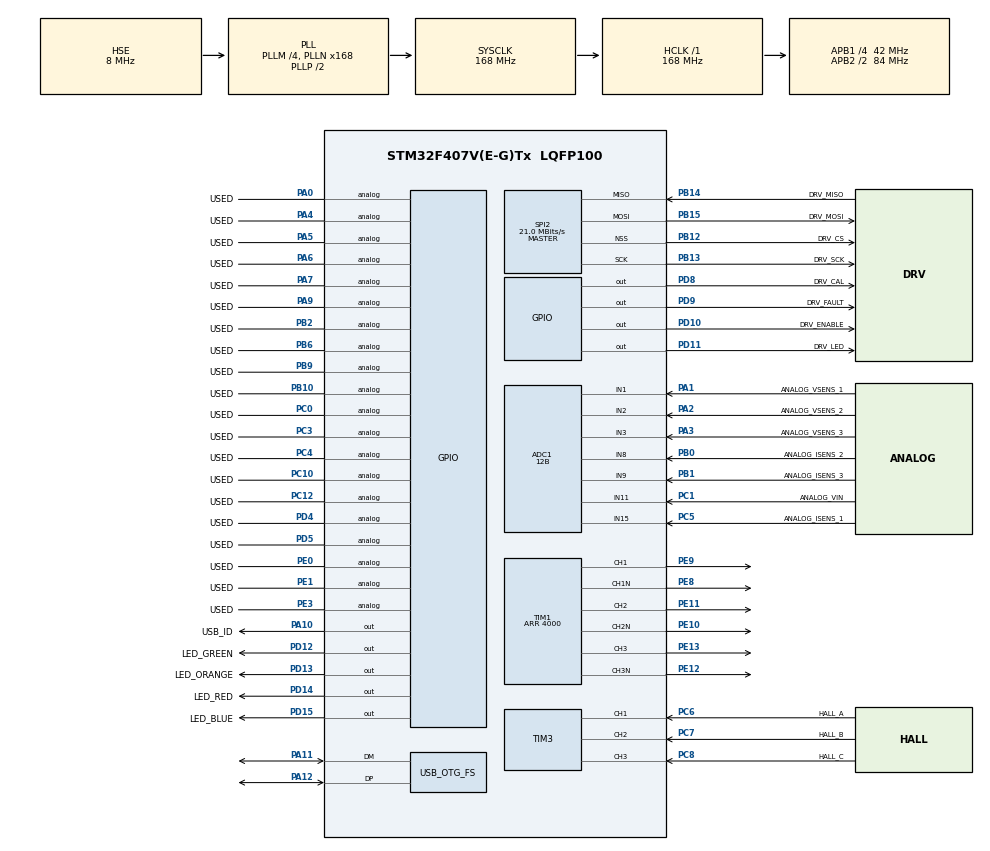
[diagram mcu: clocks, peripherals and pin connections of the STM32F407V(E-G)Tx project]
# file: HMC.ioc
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ADC1.Channel-155\#ChannelRegularConversion=ADC_CHANNEL_1
ADC1.ClockPrescaler=ADC_CLOCK_SYNC_PCLK_DIV4
ADC1.ContinuousConvMode=DISABLE
ADC1.DMAContinuousRequests=DISABLE
ADC1.DataAlign=ADC_DATAALIGN_RIGHT
ADC1.DiscontinuousConvMode=DISABLE
ADC1.EOCSelection=ADC_EOC_SINGLE_CONV
ADC1.EnableAnalogWatchDog=false
ADC1.ExternalTrigConv=ADC_SOFTWARE_START
ADC1.ExternalTrigConvEdge=ADC_EXTERNALTRIGCONVEDGE_NONE
ADC1.InjNumberOfConversion=0
ADC1.NbrOfConversion=1
ADC1.NbrOfConversionFlag=1
ADC1.Rank-155\#ChannelRegularConversion=1
ADC1.Resolution=ADC_RESOLUTION_12B
ADC1.SamplingTime-155\#ChannelRegularConversion=ADC_SAMPLETIME_3CYCLES
ADC1.ScanConvMode=DISABLE
ADC1.master=1
Mcu.Family=STM32F4
Mcu.Name=STM32F407V(E-G)Tx
Mcu.Package=LQFP100
NVIC.OTG_FS_IRQn=true\:0\:0\:false\:false\:true\:false
NVIC.PriorityGroup=NVIC_PRIORITYGROUP_4
NVIC.TIM1_TRG_COM_TIM11_IRQn=true\:0\:0\:false\:false\:true\:true
NVIC.TIM3_IRQn=true\:0\:0\:false\:false\:true\:true
PA0-WKUP.GPIO_Label=USED
PA0-WKUP.Signal=GPIO_Analog
PA1.GPIO_Label=ANALOG_VSENS_1
PA1.Signal=ADCx_IN1
PA10.GPIO_Label=USB_ID
PA10.Signal=GPIO_Output
PA11.Mode=Device_Only
PA11.Signal=USB_OTG_FS_DM
PA12.Mode=Device_Only
PA12.Signal=USB_OTG_FS_DP
PA13.Mode=Trace_Asynchronous_SW
PA13.Signal=SYS_JTMS-SWDIO
PA14.Mode=Trace_Asynchronous_SW
PA14.Signal=SYS_JTCK-SWCLK
PA2.GPIO_Label=ANALOG_VSENS_2
PA2.Signal=ADCx_IN2
PA3.GPIO_Label=ANALOG_VSENS_3
PA3.Signal=ADCx_IN3
PA4.GPIO_Label=USED
PA4.Signal=GPIO_Analog
PA5.GPIO_Label=USED
PA5.Signal=GPIO_Analog
PA6.GPIO_Label=USED
PA6.Signal=GPIO_Analog
PA7.GPIO_Label=USED
PA7.Signal=GPIO_Analog
PA9.GPIO_Label=USED
PA9.Signal=GPIO_Analog
PB0.GPIO_Label=ANALOG_ISENS_2
PB0.Signal=ADCx_IN8
PB1.GPIO_Label=ANALOG_ISENS_3
PB1.Signal=ADCx_IN9
PB10.GPIO_Label=USED
PB10.Signal=GPIO_Analog
PB12.GPIO_Label=DRV_CS
PB12.Mode=NSS_Signal_Hard_Output
PB12.Signal=SPI2_NSS
PB13.GPIO_Label=DRV_SCK
PB13.Mode=Full_Duplex_Master
PB13.Signal=SPI2_SCK
PB14.GPIO_Label=DRV_MISO
PB14.Mode=Full_Duplex_Master
PB14.Signal=SPI2_MISO
PB15.GPIO_Label=DRV_MOSI
PB15.Mode=Full_Duplex_Master
PB15.Signal=SPI2_MOSI
PB2.GPIO_Label=USED
PB2.Signal=GPIO_Analog
PB3.Mode=Trace_Asynchronous_SW
PB3.Signal=SYS_JTDO-SWO
PB6.GPIO_Label=USED
PB6.Signal=GPIO_Analog
PB9.GPIO_Label=USED
PB9.Signal=GPIO_Analog
PC0.GPIO_Label=USED
PC0.Signal=GPIO_Analog
PC1.GPIO_Label=ANALOG_VIN
PC1.Signal=ADCx_IN11
PC10.GPIO_Label=USED
PC10.Signal=GPIO_Analog
PC12.GPIO_Label=USED
PC12.Signal=GPIO_Analog
PC14-OSC32_IN.Mode=LSE-External-Oscillator
PC14-OSC32_IN.Signal=RCC_OSC32_IN
PC15-OSC32_OUT.Mode=LSE-External-Oscillator
PC15-OSC32_OUT.Signal=RCC_OSC32_OUT
PC3.GPIO_Label=USED
PC3.Signal=GPIO_Analog
PC4.GPIO_Label=USED
PC4.Signal=GPIO_Analog
PC5.GPIO_Label=ANALOG_ISENS_1
PC5.Signal=ADCx_IN15
PC6.GPIO_Label=HALL_A
PC6.Signal=S_TIM3_CH1
PC7.GPIO_Label=HALL_B
PC7.Signal=S_TIM3_CH2
PC8.GPIO_Label=HALL_C
PC8.Signal=S_TIM3_CH3
PD10.GPIO_Label=DRV_ENABLE
PD10.Signal=GPIO_Output
PD11.GPIO_Label=DRV_LED
PD11.Signal=GPIO_Output
PD12.GPIO_Label=LED_GREEN
PD12.Signal=GPIO_Output
PD13.GPIO_Label=LED_ORANGE
PD13.Signal=GPIO_Output
PD14.GPIO_Label=LED_RED
PD14.Signal=GPIO_Output
PD15.GPIO_Label=LED_BLUE
PD15.Signal=GPIO_Output
PD4.GPIO_Label=USED
PD4.Signal=GPIO_Analog
PD5.GPIO_Label=USED
PD5.Signal=GPIO_Analog
PD8.GPIO_Label=DRV_CAL
PD8.Signal=GPIO_Output
PD9.GPIO_Label=DRV_FAULT
PD9.Signal=GPIO_Output
PE0.GPIO_Label=USED
PE0.Signal=GPIO_Analog
PE1.GPIO_Label=USED
PE1.Signal=GPIO_Analog
PE10.GPIO_Speed=GPIO_SPEED_FREQ_VERY_HIGH
PE10.Mode=Output Compare2 CH2 CH2N
PE10.Signal=TIM1_CH2N
PE11.GPIO_Speed=GPIO_SPEED_FREQ_VERY_HIGH
PE11.Signal=S_TIM1_CH2
PE12.GPIO_Speed=GPIO_SPEED_FREQ_VERY_HIGH
PE12.Mode=Output Compare3 CH3 CH3N
PE12.Signal=TIM1_CH3N
PE13.GPIO_Speed=GPIO_SPEED_FREQ_VERY_HIGH
PE13.Signal=S_TIM1_CH3
PE3.GPIO_Label=USED
PE3.Signal=GPIO_Analog
PE8.GPIO_PuPd=GPIO_NOPULL
PE8.GPIO_Speed=GPIO_SPEED_FREQ_VERY_HIGH
PE8.Mode=Output Compare1 CH1 CH1N
PE8.Signal=TIM1_CH1N
PE9.GPIO_Speed=GPIO_SPEED_FREQ_VERY_HIGH
PE9.Signal=S_TIM1_CH1
PH0-OSC_IN.Mode=HSE-External-Oscillator
PH0-OSC_IN.Signal=RCC_OSC_IN
PH1-OSC_OUT.Mode=HSE-External-Oscillator
PH1-OSC_OUT.Signal=RCC_OSC_OUT
ProjectManager.HeapSize=0x200
ProjectManager.StackSize=0x400
ProjectManager.TargetToolchain=Makefile
RCC.48MHZClocksFreq_Value=48000000
RCC.AHBFreq_Value=168000000
RCC.APB1CLKDivider=RCC_HCLK_DIV4
RCC.APB1Freq_Value=42000000
RCC.APB1TimFreq_Value=84000000
RCC.APB2CLKDivider=RCC_HCLK_DIV2
RCC.APB2Freq_Value=84000000
RCC.APB2TimFreq_Value=168000000
RCC.CortexFreq_Value=168000000
RCC.HCLKFreq_Value=168000000
RCC.HSE_VALUE=8000000
RCC.HSI_VALUE=16000000
RCC.PLLM=4
RCC.PLLN=168
RCC.PLLQ=7
RCC.SYSCLKFreq_VALUE=168000000
RCC.SYSCLKSource=RCC_SYSCLKSOURCE_PLLCLK
RCC.VCOOutputFreq_Value=336000000
SH.ADCx_IN1.0=ADC1_IN1,IN1
SH.ADCx_IN11.0=ADC1_IN11,IN11
SH.ADCx_IN15.0=ADC1_IN15,IN15
SH.ADCx_IN2.0=ADC1_IN2,IN2
SH.ADCx_IN3.0=ADC1_IN3,IN3
SH.ADCx_IN8.0=ADC1_IN8,IN8
SH.ADCx_IN9.0=ADC1_IN9,IN9
SH.S_TIM1_CH1.0=TIM1_CH1,Output Compare1 CH1 CH1N
SH.S_TIM1_CH2.0=TIM1_CH2,Output Compare2 CH2 CH2N
SH.S_TIM1_CH3.0=TIM1_CH3,Output Compare3 CH3 CH3N
SH.S_TIM3_CH1.0=TIM3_CH1,Xored_Inputs_Hall_Sensor_Interface
SH.S_TIM3_CH2.0=TIM3_CH2,Xored_Inputs_Hall_Sensor_Interface
SH.S_TIM3_CH3.0=TIM3_CH3,Xored_Inputs_Hall_Sensor_Interface
SPI2.CalculateBaudRate=21.0 MBits/s
SPI2.Direction=SPI_DIRECTION_2LINES
SPI2.Mode=SPI_MODE_MASTER
SPI2.VirtualNSS=VM_NSSHARD
SPI2.VirtualType=VM_MASTER
TIM1.AutomaticOutput=TIM_AUTOMATICOUTPUT_ENABLE
TIM1.Channel-Output\ Compare1\ CH1\ CH1N=TIM_CHANNEL_1
TIM1.Channel-Output\ Compare2\ CH2\ CH2N=TIM_CHANNEL_2
TIM1.Channel-Output\ Compare3\ CH3\ CH3N=TIM_CHANNEL_3
TIM1.DeadTime=7
TIM1.OffStateIDLEMode=TIM_OSSI_ENABLE
TIM1.OffStateRunMode=TIM_OSSR_ENABLE
TIM1.Period=4000
TIM1.TIM_MasterSlaveMode=TIM_MASTERSLAVEMODE_DISABLE
USB_DEVICE.CLASS_NAME_FS=CDC
USB_DEVICE.VirtualMode-CDC_FS=Cdc
USB_DEVICE.VirtualModeFS=Cdc_FS
USB_OTG_FS.VirtualMode=Device_Only
VP_TIM1_VS_ClockSourceITR.Mode=TriggerSource_ITR2
VP_USB_DEVICE_VS_USB_DEVICE_CDC_FS.Mode=CDC_FS
board=HMC

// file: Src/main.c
/**
  ******************************************************************************
  * @file           : main.c
  * @brief          : Main program body
  ******************************************************************************
  * This notice applies to any and all portions of this file
  * that are not between comment pairs USER CODE BEGIN and
  * USER CODE END. Other portions of this file, whether
  * inserted by the user or by software development tools
  * are owned by their respective copyright owners.
  *
  * Copyright (c) 2018 STMicroelectronics International N.V.
  * All rights reserved.
  *
  * Redistribution and use in source and binary forms, with or without
  * modification, are permitted, provided that the following conditions are met:
  *
  * 1. Redistribution of source code must retain the above copyright notice,
  *    this list of conditions and the following disclaimer.
  * 2. Redistributions in binary form must reproduce the above copyright notice,
  *    this list of conditions and the following disclaimer in the documentation
  *    and/or other materials provided with the distribution.
  * 3. Neither the name of STMicroelectronics nor the names of other
  *    contributors to this software may be used to endorse or promote products
  *    derived from this software without specific written permission.
  * 4. This software, including modifications and/or derivative works of this
  *    software, must execute solely and exclusively on microcontroller or
  *    microprocessor devices manufactured by or for STMicroelectronics.
  * 5. Redistribution and use of this software other than as permitted under
  *    this license is void and will automatically terminate your rights under
  *    this license.
  *
  * THIS SOFTWARE IS PROVIDED BY STMICROELECTRONICS AND CONTRIBUTORS "AS IS"
  * AND ANY EXPRESS, IMPLIED OR STATUTORY WARRANTIES, INCLUDING, BUT NOT
  * LIMITED TO, THE IMPLIED WARRANTIES OF MERCHANTABILITY, FITNESS FOR A
  * PARTICULAR PURPOSE AND NON-INFRINGEMENT OF THIRD PARTY INTELLECTUAL PROPERTY
  * RIGHTS ARE DISCLAIMED TO THE FULLEST EXTENT PERMITTED BY LAW. IN NO EVENT
  * SHALL STMICROELECTRONICS OR CONTRIBUTORS BE LIABLE FOR ANY DIRECT, INDIRECT,
  * INCIDENTAL, SPECIAL, EXEMPLARY, OR CONSEQUENTIAL DAMAGES (INCLUDING, BUT NOT
  * LIMITED TO, PROCUREMENT OF SUBSTITUTE GOODS OR SERVICES; LOSS OF USE, DATA,
  * OR PROFITS; OR BUSINESS INTERRUPTION) HOWEVER CAUSED AND ON ANY THEORY OF
  * LIABILITY, WHETHER IN CONTRACT, STRICT LIABILITY, OR TORT (INCLUDING
  * NEGLIGENCE OR OTHERWISE) ARISING IN ANY WAY OUT OF THE USE OF THIS SOFTWARE,
  * EVEN IF ADVISED OF THE POSSIBILITY OF SUCH DAMAGE.
  *
  ******************************************************************************
  */
#include "main.h"
#include "stm32f4xx_hal.h"
#include "usb_device.h"

/* USER CODE BEGIN Includes */
#include "time.h"
#include "motor.h"
#include "usbd_cdc_if.h"
/* USER CODE END Includes */

ADC_HandleTypeDef hadc1;

SPI_HandleTypeDef hspi2;

TIM_HandleTypeDef htim1;
TIM_HandleTypeDef htim3;

/* USER CODE BEGIN PV */
/* Private variables ---------------------------------------------------------*/

/* USER CODE END PV */

void SystemClock_Config(void);
static void MX_GPIO_Init(void);
static void MX_TIM1_Init(void);
static void MX_ADC1_Init(void);
static void MX_SPI2_Init(void);
static void MX_TIM3_Init(void);

void HAL_TIM_MspPostInit(TIM_HandleTypeDef *htim);

/* USER CODE BEGIN PFP */
/* Private function prototypes -----------------------------------------------*/

/* USER CODE END PFP */

int main(void)
{

  /* MCU Configuration----------------------------------------------------------*/

  /* Reset of all peripherals, Initializes the Flash interface and the Systick. */
  HAL_Init();

  /* Configure the system clock */
  SystemClock_Config();

  /* Initialize all configured peripherals */
  MX_GPIO_Init();
  MX_TIM1_Init();
  MX_ADC1_Init();
  MX_SPI2_Init();
  MX_USB_DEVICE_Init();
  MX_TIM3_Init();

  /* Infinite loop */
	while (1)
	{

  /* USER CODE BEGIN 3 */
		static time timer = 0;

		if(time_elapsed_now(timer) > 100)
		{
			timer = time_get();

      CDC_Transmit_FS((uint8_t *)"hello\r\n", 5);

			HAL_GPIO_TogglePin(LED_BLUE_GPIO_Port, LED_BLUE_Pin);
			HAL_GPIO_TogglePin(LED_RED_GPIO_Port, LED_RED_Pin);
			HAL_GPIO_TogglePin(LED_ORANGE_GPIO_Port, LED_ORANGE_Pin);
			HAL_GPIO_TogglePin(LED_GREEN_GPIO_Port, LED_GREEN_Pin);
		}
	}
  /* USER CODE END 3 */

}

void SystemClock_Config(void)
{

  RCC_OscInitTypeDef RCC_OscInitStruct;
  RCC_ClkInitTypeDef RCC_ClkInitStruct;

    /**Configure the main internal regulator output voltage
    */
  __HAL_RCC_PWR_CLK_ENABLE();

  __HAL_PWR_VOLTAGESCALING_CONFIG(PWR_REGULATOR_VOLTAGE_SCALE1);

    /**Initializes the CPU, AHB and APB busses clocks
    */
  RCC_OscInitStruct.OscillatorType = RCC_OSCILLATORTYPE_HSE;
  RCC_OscInitStruct.HSEState = RCC_HSE_ON;
  RCC_OscInitStruct.PLL.PLLState = RCC_PLL_ON;
  RCC_OscInitStruct.PLL.PLLSource = RCC_PLLSOURCE_HSE;
  RCC_OscInitStruct.PLL.PLLM = 4;
  RCC_OscInitStruct.PLL.PLLN = 168;
  RCC_OscInitStruct.PLL.PLLP = RCC_PLLP_DIV2;
  RCC_OscInitStruct.PLL.PLLQ = 7;
  if (HAL_RCC_OscConfig(&RCC_OscInitStruct) != HAL_OK)
  {
    _Error_Handler(__FILE__, __LINE__);
  }

    /**Initializes the CPU, AHB and APB busses clocks
    */
  RCC_ClkInitStruct.ClockType = RCC_CLOCKTYPE_HCLK|RCC_CLOCKTYPE_SYSCLK
                              |RCC_CLOCKTYPE_PCLK1|RCC_CLOCKTYPE_PCLK2;
  RCC_ClkInitStruct.SYSCLKSource = RCC_SYSCLKSOURCE_PLLCLK;
  RCC_ClkInitStruct.AHBCLKDivider = RCC_SYSCLK_DIV1;
  RCC_ClkInitStruct.APB1CLKDivider = RCC_HCLK_DIV4;
  RCC_ClkInitStruct.APB2CLKDivider = RCC_HCLK_DIV2;

  if (HAL_RCC_ClockConfig(&RCC_ClkInitStruct, FLASH_LATENCY_5) != HAL_OK)
  {
    _Error_Handler(__FILE__, __LINE__);
  }

    /**Configure the Systick interrupt time
    */
  HAL_SYSTICK_Config(HAL_RCC_GetHCLKFreq()/1000);

    /**Configure the Systick
    */
  HAL_SYSTICK_CLKSourceConfig(SYSTICK_CLKSOURCE_HCLK);

  /* SysTick_IRQn interrupt configuration */
  HAL_NVIC_SetPriority(SysTick_IRQn, 0, 0);
}

/* ADC1 init function */
static void MX_ADC1_Init(void)
{

  ADC_ChannelConfTypeDef sConfig;

    /**Configure the global features of the ADC (Clock, Resolution, Data Alignment and number of conversion)
    */
  hadc1.Instance = ADC1;
  hadc1.Init.ClockPrescaler = ADC_CLOCK_SYNC_PCLK_DIV4;
  hadc1.Init.Resolution = ADC_RESOLUTION_12B;
  hadc1.Init.ScanConvMode = DISABLE;
  hadc1.Init.ContinuousConvMode = DISABLE;
  hadc1.Init.DiscontinuousConvMode = DISABLE;
  hadc1.Init.ExternalTrigConvEdge = ADC_EXTERNALTRIGCONVEDGE_NONE;
  hadc1.Init.ExternalTrigConv = ADC_SOFTWARE_START;
  hadc1.Init.DataAlign = ADC_DATAALIGN_RIGHT;
  hadc1.Init.NbrOfConversion = 1;
  hadc1.Init.DMAContinuousRequests = DISABLE;
  hadc1.Init.EOCSelection = ADC_EOC_SINGLE_CONV;
  if (HAL_ADC_Init(&hadc1) != HAL_OK)
  {
    _Error_Handler(__FILE__, __LINE__);
  }

    /**Configure for the selected ADC regular channel its corresponding rank in the sequencer and its sample time.
    */
  sConfig.Channel = ADC_CHANNEL_1;
  sConfig.Rank = 1;
  sConfig.SamplingTime = ADC_SAMPLETIME_3CYCLES;
  if (HAL_ADC_ConfigChannel(&hadc1, &sConfig) != HAL_OK)
  {
    _Error_Handler(__FILE__, __LINE__);
  }

}

/* SPI2 init function */
static void MX_SPI2_Init(void)
{

  /* SPI2 parameter configuration*/
  hspi2.Instance = SPI2;
  hspi2.Init.Mode = SPI_MODE_MASTER;
  hspi2.Init.Direction = SPI_DIRECTION_2LINES;
  hspi2.Init.DataSize = SPI_DATASIZE_8BIT;
  hspi2.Init.CLKPolarity = SPI_POLARITY_LOW;
  hspi2.Init.CLKPhase = SPI_PHASE_1EDGE;
  hspi2.Init.NSS = SPI_NSS_HARD_OUTPUT;
  hspi2.Init.BaudRatePrescaler = SPI_BAUDRATEPRESCALER_2;
  hspi2.Init.FirstBit = SPI_FIRSTBIT_MSB;
  hspi2.Init.TIMode = SPI_TIMODE_DISABLE;
  hspi2.Init.CRCCalculation = SPI_CRCCALCULATION_DISABLE;
  hspi2.Init.CRCPolynomial = 10;
  if (HAL_SPI_Init(&hspi2) != HAL_OK)
  {
    _Error_Handler(__FILE__, __LINE__);
  }

}

/* TIM1 init function */
static void MX_TIM1_Init(void)
{

  TIM_SlaveConfigTypeDef sSlaveConfig;
  TIM_MasterConfigTypeDef sMasterConfig;
  TIM_OC_InitTypeDef sConfigOC;
  TIM_BreakDeadTimeConfigTypeDef sBreakDeadTimeConfig;

  htim1.Instance = TIM1;
  htim1.Init.Prescaler = 0;
  htim1.Init.CounterMode = TIM_COUNTERMODE_UP;
  htim1.Init.Period = 4000;
  htim1.Init.ClockDivision = TIM_CLOCKDIVISION_DIV1;
  htim1.Init.RepetitionCounter = 0;
  if (HAL_TIM_Base_Init(&htim1) != HAL_OK)
  {
    _Error_Handler(__FILE__, __LINE__);
  }

  if (HAL_TIM_OC_Init(&htim1) != HAL_OK)
  {
    _Error_Handler(__FILE__, __LINE__);
  }

  sSlaveConfig.SlaveMode = TIM_SLAVEMODE_DISABLE;
  sSlaveConfig.InputTrigger = TIM_TS_ITR2;
  if (HAL_TIM_SlaveConfigSynchronization(&htim1, &sSlaveConfig) != HAL_OK)
  {
    _Error_Handler(__FILE__, __LINE__);
  }

  sMasterConfig.MasterOutputTrigger = TIM_TRGO_RESET;
  sMasterConfig.MasterSlaveMode = TIM_MASTERSLAVEMODE_DISABLE;
  if (HAL_TIMEx_MasterConfigSynchronization(&htim1, &sMasterConfig) != HAL_OK)
  {
    _Error_Handler(__FILE__, __LINE__);
  }

  sConfigOC.OCMode = TIM_OCMODE_TIMING;
  sConfigOC.Pulse = 0;
  sConfigOC.OCPolarity = TIM_OCPOLARITY_HIGH;
  sConfigOC.OCNPolarity = TIM_OCNPOLARITY_HIGH;
  sConfigOC.OCFastMode = TIM_OCFAST_DISABLE;
  sConfigOC.OCIdleState = TIM_OCIDLESTATE_RESET;
  sConfigOC.OCNIdleState = TIM_OCNIDLESTATE_RESET;
  if (HAL_TIM_OC_ConfigChannel(&htim1, &sConfigOC, TIM_CHANNEL_1) != HAL_OK)
  {
    _Error_Handler(__FILE__, __LINE__);
  }

  if (HAL_TIM_OC_ConfigChannel(&htim1, &sConfigOC, TIM_CHANNEL_2) != HAL_OK)
  {
    _Error_Handler(__FILE__, __LINE__);
  }

  if (HAL_TIM_OC_ConfigChannel(&htim1, &sConfigOC, TIM_CHANNEL_3) != HAL_OK)
  {
    _Error_Handler(__FILE__, __LINE__);
  }

  sBreakDeadTimeConfig.OffStateRunMode = TIM_OSSR_ENABLE;
  sBreakDeadTimeConfig.OffStateIDLEMode = TIM_OSSI_ENABLE;
  sBreakDeadTimeConfig.LockLevel = TIM_LOCKLEVEL_OFF;
  sBreakDeadTimeConfig.DeadTime = 7;
  sBreakDeadTimeConfig.BreakState = TIM_BREAK_DISABLE;
  sBreakDeadTimeConfig.BreakPolarity = TIM_BREAKPOLARITY_HIGH;
  sBreakDeadTimeConfig.AutomaticOutput = TIM_AUTOMATICOUTPUT_ENABLE;
  if (HAL_TIMEx_ConfigBreakDeadTime(&htim1, &sBreakDeadTimeConfig) != HAL_OK)
  {
    _Error_Handler(__FILE__, __LINE__);
  }

  HAL_TIM_MspPostInit(&htim1);

}

/* TIM3 init function */
static void MX_TIM3_Init(void)
{

  TIM_HallSensor_InitTypeDef sConfig;
  TIM_MasterConfigTypeDef sMasterConfig;

  htim3.Instance = TIM3;
  htim3.Init.Prescaler = 0;
  htim3.Init.CounterMode = TIM_COUNTERMODE_UP;
  htim3.Init.Period = 0;
  htim3.Init.ClockDivision = TIM_CLOCKDIVISION_DIV1;
  sConfig.IC1Polarity = TIM_ICPOLARITY_RISING;
  sConfig.IC1Prescaler = TIM_ICPSC_DIV1;
  sConfig.IC1Filter = 0;
  sConfig.Commutation_Delay = 0;
  if (HAL_TIMEx_HallSensor_Init(&htim3, &sConfig) != HAL_OK)
  {
    _Error_Handler(__FILE__, __LINE__);
  }

  sMasterConfig.MasterOutputTrigger = TIM_TRGO_OC2REF;
  sMasterConfig.MasterSlaveMode = TIM_MASTERSLAVEMODE_DISABLE;
  if (HAL_TIMEx_MasterConfigSynchronization(&htim3, &sMasterConfig) != HAL_OK)
  {
    _Error_Handler(__FILE__, __LINE__);
  }

}

/** Configure pins as
        * Analog
        * Input
        * Output
        * EVENT_OUT
        * EXTI
*/
static void MX_GPIO_Init(void)
{

  GPIO_InitTypeDef GPIO_InitStruct;

  /* GPIO Ports Clock Enable */
  __HAL_RCC_GPIOE_CLK_ENABLE();
  __HAL_RCC_GPIOC_CLK_ENABLE();
  __HAL_RCC_GPIOH_CLK_ENABLE();
  __HAL_RCC_GPIOA_CLK_ENABLE();
  __HAL_RCC_GPIOB_CLK_ENABLE();
  __HAL_RCC_GPIOD_CLK_ENABLE();

  /*Configure GPIO pin Output Level */
  HAL_GPIO_WritePin(GPIOD, DRV_CAL_Pin|DRV_FAULT_Pin|DRV_ENABLE_Pin|DRV_LED_Pin
                          |LED_GREEN_Pin|LED_ORANGE_Pin|LED_RED_Pin|LED_BLUE_Pin, GPIO_PIN_RESET);

  /*Configure GPIO pin Output Level */
  HAL_GPIO_WritePin(USB_ID_GPIO_Port, USB_ID_Pin, GPIO_PIN_RESET);

  /*Configure GPIO pins : USED_Pin USEDE0_Pin USEDE1_Pin */
  GPIO_InitStruct.Pin = USED_Pin|USEDE0_Pin|USEDE1_Pin;
  GPIO_InitStruct.Mode = GPIO_MODE_ANALOG;
  GPIO_InitStruct.Pull = GPIO_NOPULL;
  HAL_GPIO_Init(GPIOE, &GPIO_InitStruct);

  /*Configure GPIO pins : USEDC0_Pin USEDC3_Pin USEDC4_Pin USEDC10_Pin
                           USEDC12_Pin */
  GPIO_InitStruct.Pin = USEDC0_Pin|USEDC3_Pin|USEDC4_Pin|USEDC10_Pin
                          |USEDC12_Pin;
  GPIO_InitStruct.Mode = GPIO_MODE_ANALOG;
  GPIO_InitStruct.Pull = GPIO_NOPULL;
  HAL_GPIO_Init(GPIOC, &GPIO_InitStruct);

  /*Configure GPIO pins : USEDA0_Pin USEDA4_Pin USEDA5_Pin USEDA6_Pin
                           USEDA7_Pin USEDA9_Pin */
  GPIO_InitStruct.Pin = USEDA0_Pin|USEDA4_Pin|USEDA5_Pin|USEDA6_Pin
                          |USEDA7_Pin|USEDA9_Pin;
  GPIO_InitStruct.Mode = GPIO_MODE_ANALOG;
  GPIO_InitStruct.Pull = GPIO_NOPULL;
  HAL_GPIO_Init(GPIOA, &GPIO_InitStruct);

  /*Configure GPIO pins : USEDB2_Pin USEDB10_Pin USEDB6_Pin USEDB9_Pin */
  GPIO_InitStruct.Pin = USEDB2_Pin|USEDB10_Pin|USEDB6_Pin|USEDB9_Pin;
  GPIO_InitStruct.Mode = GPIO_MODE_ANALOG;
  GPIO_InitStruct.Pull = GPIO_NOPULL;
  HAL_GPIO_Init(GPIOB, &GPIO_InitStruct);

  /*Configure GPIO pins : DRV_CAL_Pin DRV_FAULT_Pin DRV_ENABLE_Pin DRV_LED_Pin
                           LED_GREEN_Pin LED_ORANGE_Pin LED_RED_Pin LED_BLUE_Pin */
  GPIO_InitStruct.Pin = DRV_CAL_Pin|DRV_FAULT_Pin|DRV_ENABLE_Pin|DRV_LED_Pin
                          |LED_GREEN_Pin|LED_ORANGE_Pin|LED_RED_Pin|LED_BLUE_Pin;
  GPIO_InitStruct.Mode = GPIO_MODE_OUTPUT_PP;
  GPIO_InitStruct.Pull = GPIO_NOPULL;
  GPIO_InitStruct.Speed = GPIO_SPEED_FREQ_LOW;
  HAL_GPIO_Init(GPIOD, &GPIO_InitStruct);

  /*Configure GPIO pin : USB_ID_Pin */
  GPIO_InitStruct.Pin = USB_ID_Pin;
  GPIO_InitStruct.Mode = GPIO_MODE_OUTPUT_PP;
  GPIO_InitStruct.Pull = GPIO_NOPULL;
  GPIO_InitStruct.Speed = GPIO_SPEED_FREQ_LOW;
  HAL_GPIO_Init(USB_ID_GPIO_Port, &GPIO_InitStruct);

  /*Configure GPIO pins : USEDD4_Pin USEDD5_Pin */
  GPIO_InitStruct.Pin = USEDD4_Pin|USEDD5_Pin;
  GPIO_InitStruct.Mode = GPIO_MODE_ANALOG;
  GPIO_InitStruct.Pull = GPIO_NOPULL;
  HAL_GPIO_Init(GPIOD, &GPIO_InitStruct);

}

void _Error_Handler(char *file, int line)
{
	while (1)
	{
	}
}

/************************ (C) COPYRIGHT STMicroelectronics *****END OF FILE****/
